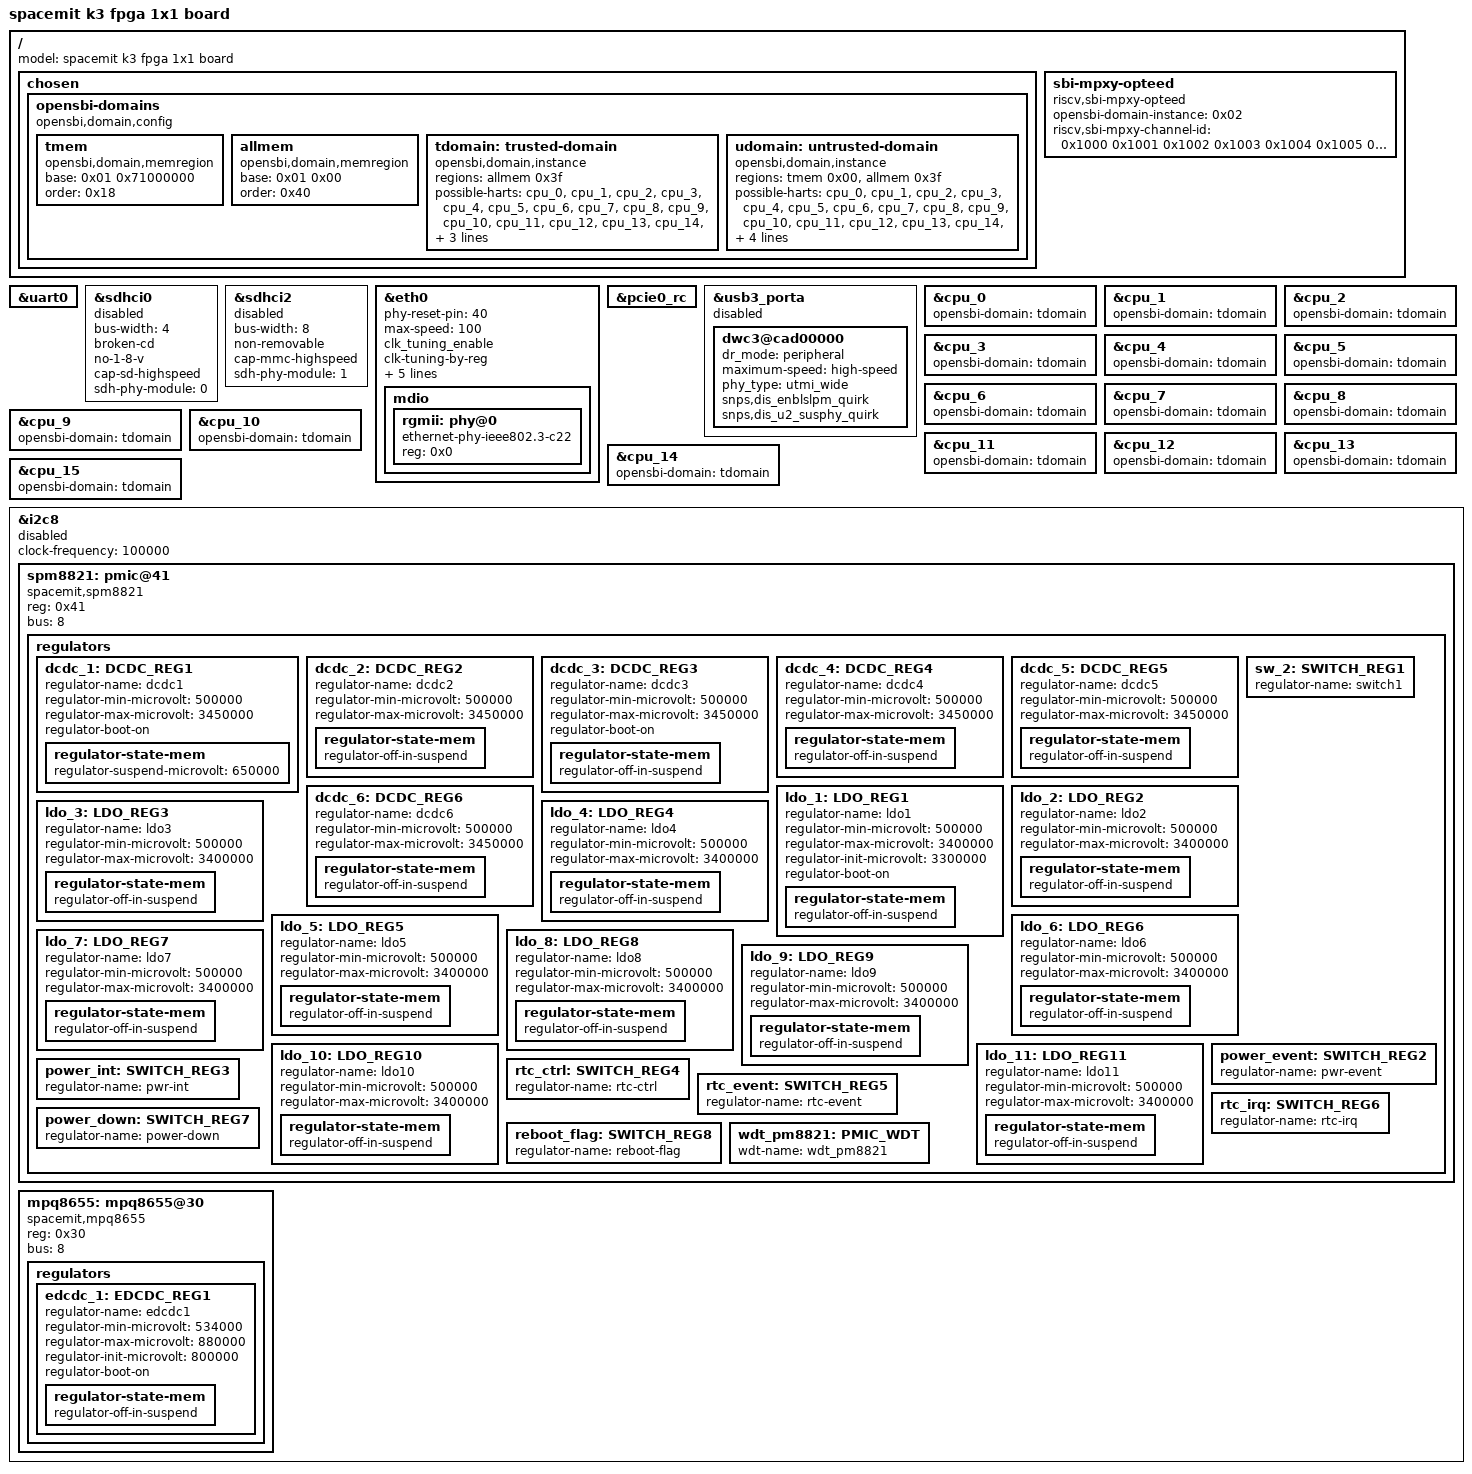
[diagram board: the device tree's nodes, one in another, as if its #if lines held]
// SPDX-License-Identifier: GPL-2.0
/*
 * finch board's base device tree configure.
 *
 * Copyright (C) 2025 SPACEMIT Micro Limited
 */

#include "k3.dtsi"
#include "k3-pinctrl.dtsi"

/ {
	model = "spacemit k3 fpga 1x1 board";
};

&uart0 {
	status = "okay";
};

&sdhci0 {
	bus-width = <4>;
	broken-cd;
	no-1-8-v;
	cap-sd-highspeed;
	sdh-phy-module = <0>;
	status = "disabled";
};

/* eMMC */
&sdhci2 {
	bus-width = <8>;
	non-removable;
	cap-mmc-highspeed;
	sdh-phy-module = <1>;
	status = "disabled";
};

&eth0 {
	phy-reset-pin = <40>;
	max-speed = <100>;
	clk_tuning_enable;
	clk-tuning-by-reg;
	tx-phase = <0>;
	rx-phase = <0>;

	phy-mode = "rgmii";
	phy-addr = <0>;
	phy-handle = <&rgmii>;

	status = "okay";

	mdio {
		#address-cells = <0x1>;
		#size-cells = <0x0>;
		rgmii: phy@0 {
			compatible = "ethernet-phy-ieee802.3-c22";
			device_type = "ethernet-phy";
			reg = <0x0>;
		};
	};
};

&pcie0_rc{
	status = "okay";
};

&usb3_porta {
	status = "disabled";
	u-boot,dm-spl;
	dwc3@cad00000 {
		dr_mode = "peripheral";
		maximum-speed = "high-speed";
		phy_type = "utmi_wide";
		snps,dis_enblslpm_quirk;
		snps,dis_u2_susphy_quirk;
		u-boot,dm-spl;
	};
};

#ifdef CONFIG_RISCV_OPTEE_SUPPORT
/ {
	chosen {
		opensbi-domains {
			compatible = "opensbi,domain,config";

			tmem: tmem {
				compatible = "opensbi,domain,memregion";
				base = <0x01 0x71000000>;
				order = <0x18>;
			};

			allmem: allmem {
				compatible = "opensbi,domain,memregion";
				base = <0x01 0x00>;
				order = <0x40>;
			};

			tdomain: trusted-domain {
				compatible = "opensbi,domain,instance";
				regions = <&allmem 0x3f>;
				possible-harts = <&cpu_0 &cpu_1 &cpu_2 &cpu_3
					&cpu_4 &cpu_5 &cpu_6 &cpu_7
					&cpu_8 &cpu_9 &cpu_10 &cpu_11
					&cpu_12 &cpu_13 &cpu_14 &cpu_15>;
				next-addr = <0x01 0x71000000>;
				next-mode = <0x01>;
				phandle = <0x02>;
			};

			udomain: untrusted-domain {
				compatible = "opensbi,domain,instance";
				regions = <&tmem 0x00>, <&allmem 0x3f>;
				possible-harts = <&cpu_0 &cpu_1 &cpu_2 &cpu_3
					&cpu_4 &cpu_5 &cpu_6 &cpu_7
					&cpu_8 &cpu_9 &cpu_10 &cpu_11
					&cpu_12 &cpu_13 &cpu_14 &cpu_15>;
				boot-hart = <&cpu_0>;
				next-addr = <0x01 0x02000000>;
				next-mode = <0x01>;
			};
		};
	};

	sbi-mpxy-opteed {
		opensbi-domain-instance = <0x02>;
		riscv,sbi-mpxy-channel-id = <0x1000 0x1001 0x1002 0x1003
					0x1004 0x1005 0x1006 0x1007
					0x1008 0x1009 0x100a 0x100b
					0x100c 0x100d 0x100e 0x100f>;
		compatible = "riscv,sbi-mpxy-opteed";
	};
};

&cpu_0 {
	opensbi-domain = <&tdomain>;
};
&cpu_1 {
	opensbi-domain = <&tdomain>;
};
&cpu_2 {
	opensbi-domain = <&tdomain>;
};
&cpu_3 {
	opensbi-domain = <&tdomain>;
};
&cpu_4 {
	opensbi-domain = <&tdomain>;
};
&cpu_5 {
	opensbi-domain = <&tdomain>;
};
&cpu_6 {
	opensbi-domain = <&tdomain>;
};
&cpu_7 {
	opensbi-domain = <&tdomain>;
};
&cpu_8 {
	opensbi-domain = <&tdomain>;
};
&cpu_9 {
	opensbi-domain = <&tdomain>;
};
&cpu_10 {
	opensbi-domain = <&tdomain>;
};
&cpu_11 {
	opensbi-domain = <&tdomain>;
};
&cpu_12 {
	opensbi-domain = <&tdomain>;
};
&cpu_13 {
	opensbi-domain = <&tdomain>;
};
&cpu_14 {
	opensbi-domain = <&tdomain>;
};
&cpu_15 {
	opensbi-domain = <&tdomain>;
};
#endif

&i2c8 {
	clock-frequency = <100000>;
	u-boot,dm-spl;
	status = "disabled";

	spm8821: pmic@41 {
		compatible = "spacemit,spm8821";
		reg = <0x41>;
		bus = <8>;
		u-boot,dm-spl;

		regulators {
			/* buck */
			dcdc_1: DCDC_REG1 {
				regulator-name = "dcdc1";
				regulator-min-microvolt = <500000>;
				regulator-max-microvolt = <3450000>;
				/* regulator-init-microvolt = <1050000>; */
				regulator-boot-on;
				u-boot,dm-spl;
				regulator-state-mem {
					regulator-suspend-microvolt = <650000>;
				};
			};

			dcdc_2: DCDC_REG2 {
				regulator-name = "dcdc2";
				regulator-min-microvolt = <500000>;
				regulator-max-microvolt = <3450000>;
				regulator-state-mem {
					regulator-off-in-suspend;
				};
			};

			dcdc_3: DCDC_REG3 {
				regulator-name = "dcdc3";
				regulator-min-microvolt = <500000>;
				regulator-max-microvolt = <3450000>;
				regulator-boot-on;
				u-boot,dm-spl;
				regulator-state-mem {
					regulator-off-in-suspend;
				};
			};

			dcdc_4: DCDC_REG4 {
				regulator-name = "dcdc4";
				regulator-min-microvolt = <500000>;
				regulator-max-microvolt = <3450000>;
				regulator-state-mem {
					regulator-off-in-suspend;
				};
			};

			dcdc_5: DCDC_REG5 {
				regulator-name = "dcdc5";
				regulator-min-microvolt = <500000>;
				regulator-max-microvolt = <3450000>;
				regulator-state-mem {
					regulator-off-in-suspend;
				};
			};

			dcdc_6: DCDC_REG6 {
				regulator-name = "dcdc6";
				regulator-min-microvolt = <500000>;
				regulator-max-microvolt = <3450000>;
				regulator-state-mem {
					regulator-off-in-suspend;
				};
			};

			/* aldo */
			ldo_1: LDO_REG1 {
				regulator-name = "ldo1";
				regulator-min-microvolt = <500000>;
				regulator-max-microvolt = <3400000>;
				regulator-init-microvolt = <3300000>;
				regulator-boot-on;
				u-boot,dm-spl;
				regulator-state-mem {
					regulator-off-in-suspend;
				};
			};

			ldo_2: LDO_REG2 {
				regulator-name = "ldo2";
				regulator-min-microvolt = <500000>;
				regulator-max-microvolt = <3400000>;
				regulator-state-mem {
					regulator-off-in-suspend;
				};
			};

			ldo_3: LDO_REG3 {
				regulator-name = "ldo3";
				regulator-min-microvolt = <500000>;
				regulator-max-microvolt = <3400000>;
				regulator-state-mem {
					regulator-off-in-suspend;
				};
			};

			ldo_4: LDO_REG4 {
				regulator-name = "ldo4";
				regulator-min-microvolt = <500000>;
				regulator-max-microvolt = <3400000>;
				regulator-state-mem {
					regulator-off-in-suspend;
				};
			};

			/* dldo */
			ldo_5: LDO_REG5 {
				regulator-name = "ldo5";
				regulator-min-microvolt = <500000>;
				regulator-max-microvolt = <3400000>;
				regulator-state-mem {
					regulator-off-in-suspend;
				};
			};

			ldo_6: LDO_REG6 {
				regulator-name = "ldo6";
				regulator-min-microvolt = <500000>;
				regulator-max-microvolt = <3400000>;
				regulator-state-mem {
					regulator-off-in-suspend;
				};
			};

			ldo_7: LDO_REG7 {
				regulator-name = "ldo7";
				regulator-min-microvolt = <500000>;
				regulator-max-microvolt = <3400000>;
				regulator-state-mem {
					regulator-off-in-suspend;
				};
			};

			ldo_8: LDO_REG8 {
				regulator-name = "ldo8";
				regulator-min-microvolt = <500000>;
				regulator-max-microvolt = <3400000>;
				regulator-state-mem {
					regulator-off-in-suspend;
				};
			};

			ldo_9: LDO_REG9 {
				regulator-name = "ldo9";
				regulator-min-microvolt = <500000>;
				regulator-max-microvolt = <3400000>;
				regulator-state-mem {
					regulator-off-in-suspend;
				};
			};

			ldo_10: LDO_REG10 {
				regulator-name = "ldo10";
				regulator-min-microvolt = <500000>;
				regulator-max-microvolt = <3400000>;
				regulator-state-mem {
					regulator-off-in-suspend;
				};
			};

			ldo_11: LDO_REG11 {
				regulator-name = "ldo11";
				regulator-min-microvolt = <500000>;
				regulator-max-microvolt = <3400000>;
				regulator-state-mem {
					regulator-off-in-suspend;
				};
			};

			sw_2: SWITCH_REG1 {
				regulator-name = "switch1";
			};

			power_event: SWITCH_REG2 {
				regulator-name = "pwr-event";
			};

			power_int: SWITCH_REG3 {
				regulator-name = "pwr-int";
			};

			rtc_ctrl: SWITCH_REG4 {
				regulator-name = "rtc-ctrl";
			};

			rtc_event: SWITCH_REG5 {
				regulator-name = "rtc-event";
			};

			rtc_irq: SWITCH_REG6 {
				regulator-name = "rtc-irq";
			};

			power_down: SWITCH_REG7 {
				regulator-name = "power-down";
			};

			reboot_flag: SWITCH_REG8 {
				regulator-name = "reboot-flag";
			};

			wdt_pm8821: PMIC_WDT {
				wdt-name = "wdt_pm8821";
			};
		};
	};

	mpq8655: mpq8655@30 {
		compatible = "spacemit,mpq8655";
		reg = <0x30>;
		bus = <8>;
		u-boot,dm-spl;

		regulators {
			u-boot,dm-spl;

			edcdc_1: EDCDC_REG1 {
				regulator-name = "edcdc1";
				regulator-min-microvolt = <534000>;
				regulator-max-microvolt = <880000>;
				regulator-init-microvolt = <800000>;
				regulator-boot-on;
				u-boot,dm-spl;
				regulator-state-mem {
					regulator-off-in-suspend;
				};
			};
		};
	};
};
